AUTOSAR XML (schema 4-2-2)
package /ComponentTypes
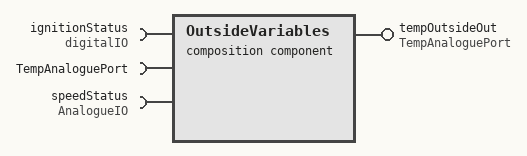
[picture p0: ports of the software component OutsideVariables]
  composition sw component type OutsideVariables: data-type-mapping=[speedMapSet, speedMapSet, speedMapSet, speedMapSet]
    require port ignitionStatus: required-interface=digitalIO
    provide port tempOutsideOut: provided-interface=TempAnaloguePort
    require port TempAnaloguePort: required-interface=TempAnaloguePort
    require port speedStatus: required-interface=AnalogueIO
    component ApTempOutside: type=tempOutside
    component APStart: type=APStart
    delegate ApTempOutside.tempObtained <-> outer port tempOutsideOut
    delegate ApTempOutside.TempAnaloguePort <-> outer port TempAnaloguePort
    delegate APStart.ignition <-> outer port ignitionStatus
    delegate APStart.speed <-> outer port speedStatus
